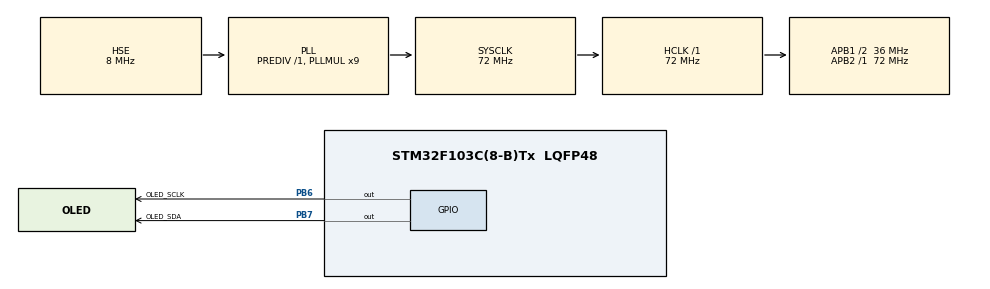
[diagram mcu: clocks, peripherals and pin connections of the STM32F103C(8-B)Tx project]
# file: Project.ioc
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Mcu.Family=STM32F1
Mcu.Name=STM32F103C(8-B)Tx
Mcu.Package=LQFP48
NVIC.PriorityGroup=NVIC_PRIORITYGROUP_4
PA13.Mode=Serial_Wire
PA13.Signal=SYS_JTMS-SWDIO
PA14.Mode=Serial_Wire
PA14.Signal=SYS_JTCK-SWCLK
PB6.GPIO_Label=OLED_SCLK
PB6.GPIO_ModeDefaultOutputPP=GPIO_MODE_OUTPUT_PP
PB6.GPIO_PuPd=GPIO_PULLUP
PB6.GPIO_Speed=GPIO_SPEED_FREQ_HIGH
PB6.PinState=GPIO_PIN_SET
PB6.Signal=GPIO_Output
PB7.GPIO_Label=OLED_SDA
PB7.GPIO_ModeDefaultOutputPP=GPIO_MODE_OUTPUT_PP
PB7.GPIO_PuPd=GPIO_PULLUP
PB7.GPIO_Speed=GPIO_SPEED_FREQ_HIGH
PB7.PinState=GPIO_PIN_SET
PB7.Signal=GPIO_Output
PD0-OSC_IN.Mode=HSE-External-Oscillator
PD0-OSC_IN.Signal=RCC_OSC_IN
PD1-OSC_OUT.Mode=HSE-External-Oscillator
PD1-OSC_OUT.Signal=RCC_OSC_OUT
ProjectManager.HeapSize=0x200
ProjectManager.StackSize=0x400
ProjectManager.TargetToolchain=MDK-ARM V5
RCC.AHBFreq_Value=72000000
RCC.APB1CLKDivider=RCC_HCLK_DIV2
RCC.APB1Freq_Value=36000000
RCC.APB1TimFreq_Value=72000000
RCC.APB2Freq_Value=72000000
RCC.APB2TimFreq_Value=72000000
RCC.HCLKFreq_Value=72000000
RCC.PLLMUL=RCC_PLL_MUL9
RCC.PLLSourceVirtual=RCC_PLLSOURCE_HSE
RCC.SYSCLKFreq_VALUE=72000000
RCC.SYSCLKSource=RCC_SYSCLKSOURCE_PLLCLK
RCC.USBFreq_Value=72000000
board=custom

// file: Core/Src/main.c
/* USER CODE BEGIN Header */
/**
  ******************************************************************************
  * @file           : main.c
  * @brief          : Main program body
  ******************************************************************************
  * @attention
  *
  * Copyright (c) 2024 STMicroelectronics.
  * All rights reserved.
  *
  * This software is licensed under terms that can be found in the LICENSE file
  * in the root directory of this software component.
  * If no LICENSE file comes with this software, it is provided AS-IS.
  *
  ******************************************************************************
  */
/* USER CODE END Header */
#include "main.h"
#include "gpio.h"

/* USER CODE BEGIN Includes */
#include "iic_oled.h"
/* USER CODE END Includes */

void SystemClock_Config(void);

int main(void)
{

  /* MCU Configuration--------------------------------------------------------*/

  /* Reset of all peripherals, Initializes the Flash interface and the Systick. */
  HAL_Init();

  /* Configure the system clock */
  SystemClock_Config();

  /* Initialize all configured peripherals */
  MX_GPIO_Init();
  /* USER CODE BEGIN 2 */
	OLED_Init();
	OLED_Clear();
  /* USER CODE END 2 */

  /* Infinite loop */
  while (1)
  {
		OLED_ShowChar(0 , 1 , 'H' , FSIZE8_6 , 1);//显示单个字母 H
		OLED_ShowChar(0 , 9 , 'H' , FSIZE12_6 , 1);
		OLED_ShowChar(0 , 22 , 'H' , FSIZE16_8 , 1);
		OLED_ShowChar(0 , 39 , 'H' , FSIZE24_12 , 1);
		HAL_Delay(500);
		OLED_ClearRAM();//清除缓存和OLED显示

		OLED_ShowStr(0 , 1 , (unsigned char *)"Hello" , FSIZE8_6 , 1);//显示字符串 Hello
		OLED_ShowStr(0 , 9 , (unsigned char *)"Hello" , FSIZE12_6 , 1);
		OLED_ShowStr(0 , 22 ,(unsigned char *)"Hello" , FSIZE16_8 , 1);
		OLED_ShowStr(0 , 39 ,(unsigned char *)"Hello" , FSIZE24_12 , 1);
		HAL_Delay(500);
		OLED_ClearRAM();//清除缓存和OLED显示

		OLED_ShowChinese(0 , 9 , (unsigned char *)"教" , FSIZE12_6 , 1);//显示中文文字
		OLED_ShowChinese(0 , 22 , (unsigned char *)"教" , FSIZE16_8 , 1);
		OLED_ShowChinese(0 , 39 , (unsigned char *)"教" , FSIZE24_12 , 1);
		HAL_Delay(500);
		OLED_ClearRAM();//清除缓存和OLED显示

		OLED_ShowStringChinese(0 , 9 , (unsigned char *)"风标教育/FBEDU"  , FSIZE12_6 , 1);//显示中文文字加英文字符串
		OLED_ShowStringChinese(0 , 22 ,(unsigned char *)"风标教育/FBEDU"  , FSIZE16_8 , 1);
		OLED_ShowStringChinese(0 , 39 ,(unsigned char *)"风标教育/FBEDU"  , FSIZE24_12 , 1);
		HAL_Delay(500);
		OLED_ClearRAM();//清除缓存和OLED显示

		OLED_DrawLine( 0 , 0 , 127 ,63 , 1, 1);//画线:从0，0坐标到127，63坐标
		HAL_Delay(500);
		OLED_DrawLine( 0 , 0 , 127 ,63 , 0, 1);//清除画线
		HAL_Delay(500);

		OLED_DrawRectangle( 0 , 10 , 120 ,60 , 1, 1);//画矩形,从0，0坐标到120，60坐标
		HAL_Delay(500);
		OLED_DrawRectangle( 0 , 10 , 120 ,60 , 0, 1);//清除矩形
		HAL_Delay(500);

		LCD_DrawCircle( 64 , 32 , 20  , 1, 1);//画圆,圆心坐标为64，32，半径为20
		HAL_Delay(500);
		LCD_DrawCircle( 64 , 32 , 20  , 0, 1);//清除圆
		HAL_Delay(500);

		OLED_ShowBMP(0 , 0 , 128 , 64 , BMP1 ,1);//显示BMP图片1
		HAL_Delay(500);
		OLED_ShowBMP(0 , 0 , 128 , 64 , BMP3 , 1);//显示BMP图片3
		HAL_Delay(500);
		OLED_ClearRAM();//清除缓存和OLED显示
		HAL_Delay(500);
  }
}

void SystemClock_Config(void)
{
  RCC_OscInitTypeDef RCC_OscInitStruct = {0};
  RCC_ClkInitTypeDef RCC_ClkInitStruct = {0};

  /** Initializes the RCC Oscillators according to the specified parameters
  * in the RCC_OscInitTypeDef structure.
  */
  RCC_OscInitStruct.OscillatorType = RCC_OSCILLATORTYPE_HSE;
  RCC_OscInitStruct.HSEState = RCC_HSE_ON;
  RCC_OscInitStruct.HSEPredivValue = RCC_HSE_PREDIV_DIV1;
  RCC_OscInitStruct.HSIState = RCC_HSI_ON;
  RCC_OscInitStruct.PLL.PLLState = RCC_PLL_ON;
  RCC_OscInitStruct.PLL.PLLSource = RCC_PLLSOURCE_HSE;
  RCC_OscInitStruct.PLL.PLLMUL = RCC_PLL_MUL9;
  if (HAL_RCC_OscConfig(&RCC_OscInitStruct) != HAL_OK)
  {
    Error_Handler();
  }

  /** Initializes the CPU, AHB and APB buses clocks
  */
  RCC_ClkInitStruct.ClockType = RCC_CLOCKTYPE_HCLK|RCC_CLOCKTYPE_SYSCLK
                              |RCC_CLOCKTYPE_PCLK1|RCC_CLOCKTYPE_PCLK2;
  RCC_ClkInitStruct.SYSCLKSource = RCC_SYSCLKSOURCE_PLLCLK;
  RCC_ClkInitStruct.AHBCLKDivider = RCC_SYSCLK_DIV1;
  RCC_ClkInitStruct.APB1CLKDivider = RCC_HCLK_DIV2;
  RCC_ClkInitStruct.APB2CLKDivider = RCC_HCLK_DIV1;

  if (HAL_RCC_ClockConfig(&RCC_ClkInitStruct, FLASH_LATENCY_2) != HAL_OK)
  {
    Error_Handler();
  }
}

void Error_Handler(void)
{
  __disable_irq();
  while (1)
  {
  }
}
